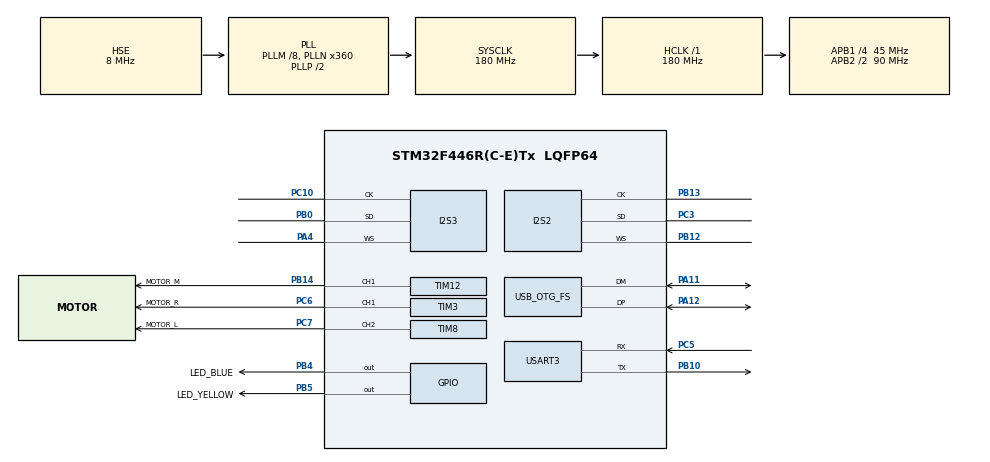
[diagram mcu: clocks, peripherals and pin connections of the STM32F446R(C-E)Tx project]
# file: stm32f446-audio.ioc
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Dma.Request0=SPI2_RX
Dma.Request1=SPI3_RX
Dma.Request2=USART3_RX
Dma.Request3=USART3_TX
Dma.SPI2_RX.0.Direction=DMA_PERIPH_TO_MEMORY
Dma.SPI2_RX.0.FIFOMode=DMA_FIFOMODE_DISABLE
Dma.SPI2_RX.0.Instance=DMA1_Stream3
Dma.SPI2_RX.0.MemDataAlignment=DMA_MDATAALIGN_HALFWORD
Dma.SPI2_RX.0.MemInc=DMA_MINC_ENABLE
Dma.SPI2_RX.0.Mode=DMA_CIRCULAR
Dma.SPI2_RX.0.PeriphDataAlignment=DMA_PDATAALIGN_HALFWORD
Dma.SPI2_RX.0.PeriphInc=DMA_PINC_DISABLE
Dma.SPI2_RX.0.Priority=DMA_PRIORITY_MEDIUM
Dma.SPI3_RX.1.Direction=DMA_PERIPH_TO_MEMORY
Dma.SPI3_RX.1.FIFOMode=DMA_FIFOMODE_DISABLE
Dma.SPI3_RX.1.Instance=DMA1_Stream0
Dma.SPI3_RX.1.MemDataAlignment=DMA_MDATAALIGN_HALFWORD
Dma.SPI3_RX.1.MemInc=DMA_MINC_ENABLE
Dma.SPI3_RX.1.Mode=DMA_CIRCULAR
Dma.SPI3_RX.1.PeriphDataAlignment=DMA_PDATAALIGN_HALFWORD
Dma.SPI3_RX.1.PeriphInc=DMA_PINC_DISABLE
Dma.SPI3_RX.1.Priority=DMA_PRIORITY_MEDIUM
Dma.USART3_RX.2.Direction=DMA_PERIPH_TO_MEMORY
Dma.USART3_RX.2.FIFOMode=DMA_FIFOMODE_DISABLE
Dma.USART3_RX.2.Instance=DMA1_Stream1
Dma.USART3_RX.2.MemDataAlignment=DMA_MDATAALIGN_BYTE
Dma.USART3_RX.2.MemInc=DMA_MINC_ENABLE
Dma.USART3_RX.2.Mode=DMA_NORMAL
Dma.USART3_RX.2.PeriphDataAlignment=DMA_PDATAALIGN_BYTE
Dma.USART3_RX.2.PeriphInc=DMA_PINC_DISABLE
Dma.USART3_RX.2.Priority=DMA_PRIORITY_LOW
Dma.USART3_TX.3.Direction=DMA_MEMORY_TO_PERIPH
Dma.USART3_TX.3.FIFOMode=DMA_FIFOMODE_DISABLE
Dma.USART3_TX.3.Instance=DMA1_Stream4
Dma.USART3_TX.3.MemDataAlignment=DMA_MDATAALIGN_BYTE
Dma.USART3_TX.3.MemInc=DMA_MINC_ENABLE
Dma.USART3_TX.3.Mode=DMA_NORMAL
Dma.USART3_TX.3.PeriphDataAlignment=DMA_PDATAALIGN_BYTE
Dma.USART3_TX.3.PeriphInc=DMA_PINC_DISABLE
Dma.USART3_TX.3.Priority=DMA_PRIORITY_LOW
I2S2.AudioFreq=I2S_AUDIOFREQ_16K
I2S2.DataFormat=I2S_DATAFORMAT_24B
I2S2.ErrorAudioFreq=0.0 %
I2S2.FullDuplexMode=I2S_FULLDUPLEXMODE_DISABLE
I2S2.Instance=SPI$Index
I2S2.Mode=I2S_MODE_MASTER_RX
I2S2.RealAudioFreq=16.0 KHz
I2S2.VirtualMode=I2S_MODE_MASTER
I2S3.AudioFreq=I2S_AUDIOFREQ_16K
I2S3.DataFormat=I2S_DATAFORMAT_24B
I2S3.ErrorAudioFreq=0.0 %
I2S3.FullDuplexMode=I2S_FULLDUPLEXMODE_DISABLE
I2S3.Instance=SPI$Index
I2S3.Mode=I2S_MODE_MASTER_RX
I2S3.RealAudioFreq=16.0 KHz
I2S3.VirtualMode=I2S_MODE_MASTER
Mcu.Family=STM32F4
Mcu.Name=STM32F446R(C-E)Tx
Mcu.Package=LQFP64
NVIC.DMA1_Stream0_IRQn=true\:0\:0\:false\:false\:true\:false\:true\:true
NVIC.DMA1_Stream1_IRQn=true\:1\:0\:true\:false\:true\:false\:true\:true
NVIC.DMA1_Stream3_IRQn=true\:0\:0\:false\:false\:true\:false\:true\:true
NVIC.DMA1_Stream4_IRQn=true\:1\:0\:true\:false\:true\:false\:true\:true
NVIC.OTG_FS_IRQn=true\:0\:0\:true\:false\:true\:true\:true\:true
NVIC.PriorityGroup=NVIC_PRIORITYGROUP_4
NVIC.USART3_IRQn=true\:1\:0\:true\:false\:true\:true\:true\:true
PA11.Mode=Device_Only
PA11.Signal=USB_OTG_FS_DM
PA12.Mode=Device_Only
PA12.Signal=USB_OTG_FS_DP
PA13.Mode=Serial_Wire
PA13.Signal=SYS_JTMS-SWDIO
PA14.Mode=Serial_Wire
PA14.Signal=SYS_JTCK-SWCLK
PA4.Mode=Half_Duplex_Master
PA4.Signal=I2S3_WS
PB0.Mode=Half_Duplex_Master
PB0.Signal=I2S3_SD
PB10.Mode=Asynchronous
PB10.Signal=USART3_TX
PB12.Mode=Half_Duplex_Master
PB12.Signal=I2S2_WS
PB13.Mode=Half_Duplex_Master
PB13.Signal=I2S2_CK
PB14.GPIO_Label=MOTOR_M
PB14.GPIO_Speed=GPIO_SPEED_FREQ_VERY_HIGH
PB14.Signal=S_TIM12_CH1
PB4.GPIO_Label=LED_BLUE
PB4.PinState=GPIO_PIN_SET
PB4.Signal=GPIO_Output
PB5.GPIO_Label=LED_YELLOW
PB5.PinState=GPIO_PIN_SET
PB5.Signal=GPIO_Output
PC10.Mode=Half_Duplex_Master
PC10.Signal=I2S3_CK
PC3.Mode=Half_Duplex_Master
PC3.Signal=I2S2_SD
PC5.Mode=Asynchronous
PC5.Signal=USART3_RX
PC6.GPIO_Label=MOTOR_R
PC6.GPIO_Speed=GPIO_SPEED_FREQ_VERY_HIGH
PC6.Signal=S_TIM3_CH1
PC7.GPIO_Label=MOTOR_L
PC7.GPIO_Speed=GPIO_SPEED_FREQ_VERY_HIGH
PC7.Signal=S_TIM8_CH2
PH0-OSC_IN.Mode=HSE-External-Oscillator
PH0-OSC_IN.Signal=RCC_OSC_IN
PH1-OSC_OUT.Mode=HSE-External-Oscillator
PH1-OSC_OUT.Signal=RCC_OSC_OUT
ProjectManager.HeapSize=0xA00
ProjectManager.StackSize=0x600
ProjectManager.TargetToolchain=Makefile
RCC.AHBFreq_Value=180000000
RCC.APB1CLKDivider=RCC_HCLK_DIV4
RCC.APB1Freq_Value=45000000
RCC.APB1TimFreq_Value=90000000
RCC.APB2CLKDivider=RCC_HCLK_DIV2
RCC.APB2Freq_Value=90000000
RCC.APB2TimFreq_Value=180000000
RCC.CortexFreq_Value=180000000
RCC.HCLKFreq_Value=180000000
RCC.HSE_VALUE=8000000
RCC.I2S2CLockSelection=RCC_I2SAPB2CLKSOURCE_EXT
RCC.PLLI2SM=4
RCC.PLLI2SR=5
RCC.PLLM=8
RCC.PLLN=360
RCC.PLLQ=7
RCC.PLLSAIM=4
RCC.PLLSAIN=96
RCC.PLLSAIP=RCC_PLLSAIP_DIV4
RCC.PLLSourceVirtual=RCC_PLLSOURCE_HSE
RCC.RCC_MCO1Source=RCC_MCO1SOURCE_HSE
RCC.SYSCLKFreq_VALUE=180000000
RCC.SYSCLKSource=RCC_SYSCLKSOURCE_PLLCLK
RCC.USBCLockSelection=RCC_CLK48CLKSOURCE_PLLSAIP
RCC.USBFreq_Value=48000000
RCC.VCOOutputFreq_Value=360000000
SH.S_TIM12_CH1.0=TIM12_CH1,PWM Generation1 CH1
SH.S_TIM3_CH1.0=TIM3_CH1,PWM Generation1 CH1
SH.S_TIM8_CH2.0=TIM8_CH2,PWM Generation2 CH2
TIM12.AutoReloadPreload=TIM_AUTORELOAD_PRELOAD_ENABLE
TIM12.Channel-PWM\ Generation1\ CH1=TIM_CHANNEL_1
TIM12.Period=255
TIM12.Prescaler=1
TIM3.AutoReloadPreload=TIM_AUTORELOAD_PRELOAD_ENABLE
TIM3.Channel-PWM\ Generation1\ CH1=TIM_CHANNEL_1
TIM3.Period=255
TIM8.AutoReloadPreload=TIM_AUTORELOAD_PRELOAD_ENABLE
TIM8.Channel-PWM\ Generation2\ CH2=TIM_CHANNEL_2
TIM8.Period=255
TIM8.Prescaler=1
USART3.VirtualMode=VM_ASYNC
USB_DEVICE.CLASS_NAME_FS=AUDIO
USB_DEVICE.MANUFACTURER_STRING-AUDIO_FS=ISDN4002
USB_DEVICE.PID_AUDIO_FS=0x5731
USB_DEVICE.PRODUCT_STRING_AUDIO_FS=ISDN4002's Microphone
USB_DEVICE.USBD_AUDIO_FREQ-AUDIO_FS=16000
USB_DEVICE.USBD_MAX_NUM_INTERFACES-AUDIO_FS=2
USB_DEVICE.VID-AUDIO_FS=0x0483
USB_DEVICE.VirtualMode-AUDIO_FS=Audio
USB_DEVICE.VirtualModeFS=Audio_FS
USB_OTG_FS.VirtualMode=Device_Only
VP_TIM12_VS_ClockSourceINT.Mode=Internal
VP_TIM3_VS_ClockSourceINT.Mode=Internal
VP_TIM8_VS_ClockSourceINT.Mode=Internal
VP_USB_DEVICE_VS_USB_DEVICE_AUDIO_FS.Mode=AUDIO_FS
board=custom

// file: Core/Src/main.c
/* USER CODE BEGIN Header */
/**
 ******************************************************************************
 * @file           : main.c
 * @brief          : Main program body
 ******************************************************************************
 * @attention
 *
 * Copyright (c) 2023 STMicroelectronics.
 * All rights reserved.
 *
 * This software is licensed under terms that can be found in the LICENSE file
 * in the root directory of this software component.
 * If no LICENSE file comes with this software, it is provided AS-IS.
 *
 ******************************************************************************
 */
/* USER CODE END Header */
#include "main.h"

#include "dma.h"
#include "gpio.h"
#include "i2s.h"
#include "tim.h"
#include "usart.h"
#include "usb_device.h"

/* USER CODE BEGIN Includes */
#include "SEGGER_SYSVIEW.h"
#include "audio_sample.h"
#include "message_controller.h"
#include "sound_localization.h"
#include "vibration_motor.h"

/* USER CODE END Includes */

void SystemClock_Config(void);
void PeriphCommonClock_Config(void);

int main(void)
{

  /* MCU Configuration--------------------------------------------------------*/

  /* Reset of all peripherals, Initializes the Flash interface and the Systick. */
  HAL_Init();

  /* Configure the system clock */
  SystemClock_Config();

  /* Configure the peripherals common clocks */
  PeriphCommonClock_Config();

  /* USER CODE BEGIN SysInit */
  SEGGER_SYSVIEW_Conf();
  SEGGER_SYSVIEW_NameMarker(1, "Motor_L");
  /* USER CODE END SysInit */

  /* Initialize all configured peripherals */
  MX_GPIO_Init();
  MX_DMA_Init();
  MX_I2S2_Init();
  MX_I2S3_Init();
  MX_TIM3_Init();
  MX_TIM8_Init();
  MX_TIM12_Init();
  MX_USART3_UART_Init();
  MX_USB_DEVICE_Init();

  /* USER CODE BEGIN 2 */

  audioStartRecord_DMA();
  message_controller_init();
  /* USER CODE END 2 */

  /* Infinite loop */
  while (1) {

    /* USER CODE BEGIN 3 */
    led_loop();
    vibration_motor_loop();
  }
  /* USER CODE END 3 */
}

void SystemClock_Config(void)
{
  RCC_OscInitTypeDef RCC_OscInitStruct = {0};
  RCC_ClkInitTypeDef RCC_ClkInitStruct = {0};

  /** Configure the main internal regulator output voltage
   */
  __HAL_RCC_PWR_CLK_ENABLE();
  __HAL_PWR_VOLTAGESCALING_CONFIG(PWR_REGULATOR_VOLTAGE_SCALE1);

  /** Initializes the RCC Oscillators according to the specified parameters
   * in the RCC_OscInitTypeDef structure.
   */
  RCC_OscInitStruct.OscillatorType = RCC_OSCILLATORTYPE_HSE;
  RCC_OscInitStruct.HSEState = RCC_HSE_ON;
  RCC_OscInitStruct.PLL.PLLState = RCC_PLL_ON;
  RCC_OscInitStruct.PLL.PLLSource = RCC_PLLSOURCE_HSE;
  RCC_OscInitStruct.PLL.PLLM = 8;
  RCC_OscInitStruct.PLL.PLLN = 360;
  RCC_OscInitStruct.PLL.PLLP = RCC_PLLP_DIV2;
  RCC_OscInitStruct.PLL.PLLQ = 7;
  RCC_OscInitStruct.PLL.PLLR = 2;
  if (HAL_RCC_OscConfig(&RCC_OscInitStruct) != HAL_OK) {
    Error_Handler();
  }

  /** Activate the Over-Drive mode
   */
  if (HAL_PWREx_EnableOverDrive() != HAL_OK) {
    Error_Handler();
  }

  /** Initializes the CPU, AHB and APB buses clocks
   */
  RCC_ClkInitStruct.ClockType = RCC_CLOCKTYPE_HCLK | RCC_CLOCKTYPE_SYSCLK | RCC_CLOCKTYPE_PCLK1 | RCC_CLOCKTYPE_PCLK2;
  RCC_ClkInitStruct.SYSCLKSource = RCC_SYSCLKSOURCE_PLLCLK;
  RCC_ClkInitStruct.AHBCLKDivider = RCC_SYSCLK_DIV1;
  RCC_ClkInitStruct.APB1CLKDivider = RCC_HCLK_DIV4;
  RCC_ClkInitStruct.APB2CLKDivider = RCC_HCLK_DIV2;

  if (HAL_RCC_ClockConfig(&RCC_ClkInitStruct, FLASH_LATENCY_5) != HAL_OK) {
    Error_Handler();
  }
}

void PeriphCommonClock_Config(void)
{
  RCC_PeriphCLKInitTypeDef PeriphClkInitStruct = {0};

  /** Initializes the peripherals clock
   */
  PeriphClkInitStruct.PeriphClockSelection = RCC_PERIPHCLK_I2S_APB1;
  PeriphClkInitStruct.PLLI2S.PLLI2SN = 192;
  PeriphClkInitStruct.PLLI2S.PLLI2SP = RCC_PLLI2SP_DIV2;
  PeriphClkInitStruct.PLLI2S.PLLI2SM = 4;
  PeriphClkInitStruct.PLLI2S.PLLI2SR = 5;
  PeriphClkInitStruct.PLLI2S.PLLI2SQ = 2;
  PeriphClkInitStruct.PLLI2SDivQ = 1;
  PeriphClkInitStruct.I2sApb1ClockSelection = RCC_I2SAPB1CLKSOURCE_PLLI2S;
  if (HAL_RCCEx_PeriphCLKConfig(&PeriphClkInitStruct) != HAL_OK) {
    Error_Handler();
  }
}

__attribute__((optimize("O0"))) void Error_Handler()
{
  __disable_irq();

  uint32_t tick = 0;
  for (;;) {
    ++tick;
    if (tick >= 4000000UL) {
      tick = 0;
      HAL_GPIO_TogglePin(LED_YELLOW_GPIO_Port, LED_YELLOW_Pin);
    }
  }
}
